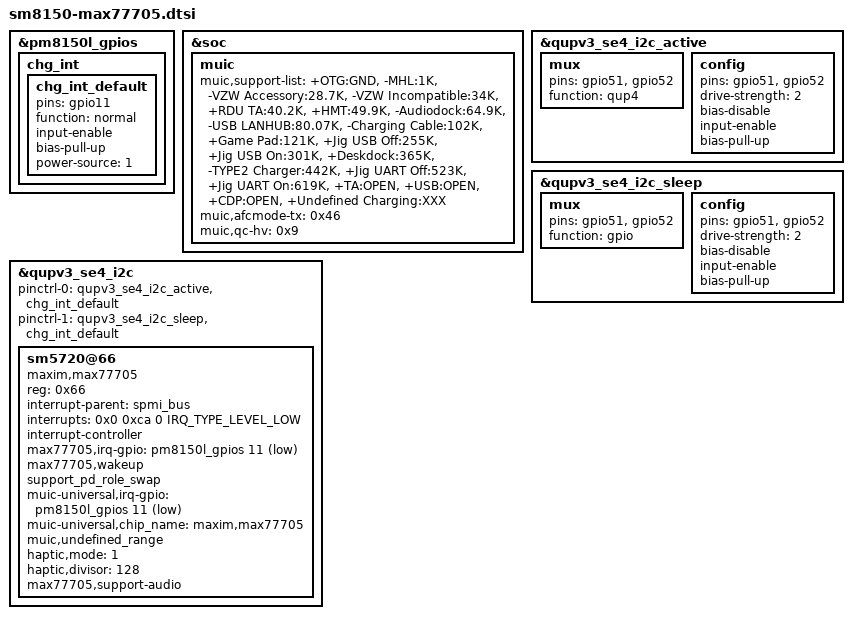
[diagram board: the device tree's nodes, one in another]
/* Copyright (c) 2012, The Linux Foundation. All rights reserved.
 *
 * This program is free software; you can redistribute it and/or modify
 * it under the terms of the GNU General Public License version 2 and
 * only version 2 as published by the Free Software Foundation.
 *
 * This program is distributed in the hope that it will be useful,
 * but WITHOUT ANY WARRANTY; without even the implied warranty of
 * MERCHANTABILITY or FITNESS FOR A PARTICULAR PURPOSE.  See the
 * GNU General Public License for more details.
 */

&pm8150l_gpios {
	chg_int {
		chg_int_default: chg_int_default {
			pins = "gpio11";
			function = "normal";
			input-enable;
			bias-pull-up;
			power-source = <1>;
		};
	};
};

&soc {
	muic {
		status = "okay";
		muic,support-list = "+OTG:GND",
				"-MHL:1K",
				"-VZW Accessory:28.7K",
				"-VZW Incompatible:34K",
				"+RDU TA:40.2K",
				"+HMT:49.9K",
				"-Audiodock:64.9K",
				"-USB LANHUB:80.07K",
				"-Charging Cable:102K",
				"+Game Pad:121K",
				"+Jig USB Off:255K",
				"+Jig USB On:301K",
				"+Deskdock:365K",
				"-TYPE2 Charger:442K",
				"+Jig UART Off:523K",
				"+Jig UART On:619K",
				"+TA:OPEN",
				"+USB:OPEN",
				"+CDP:OPEN",
				"+Undefined Charging:XXX";
		muic,afcmode-tx = /bits/ 8 <0x46>;
		muic,qc-hv = /bits/ 8 <0x9>;
	};
#if 0
	samsung,vibrator {
		compatible = "samsung_vib";
		pinctrl-names = "tlmm_motor_active","tlmm_motor_suspend";
		pinctrl-0 = <&motor_pwm_active>;
		pinctrl-1 = <&motor_pwm_suspend>;
		samsung,vib_pwm = <&tlmm 136 0>;
		samsung,vib_power = <&pm8150_gpios 10 0>;
		samsung,gp_clk = <0x00164000>;	// Address of GP1 clock
		samsung,chip_model = <4>;	// using max77705 driver
		samsung,support_multi_freq = <1>;
		status = "ok";
	};
#endif
};

		/* SE 4 pin mappings */
&qupv3_se4_i2c_active {
	mux {
		pins = "gpio51", "gpio52";
		function = "qup4";
	};

	config {
		pins = "gpio51", "gpio52";
		drive-strength = <2>;
		bias-disable;
		input-enable;
		bias-pull-up;
	};
};

&qupv3_se4_i2c_sleep {
	mux {
		pins = "gpio51", "gpio52";
		function = "gpio";
	};

	config {
		pins = "gpio51", "gpio52";
		drive-strength = <2>;
		bias-disable;
		input-enable;
		bias-pull-up;
	};
};

&qupv3_se4_i2c {
	status = "ok";

	pinctrl-0 = <&qupv3_se4_i2c_active &chg_int_default>;
	pinctrl-1 = <&qupv3_se4_i2c_sleep &chg_int_default>;

	sm5720@66 {
		compatible = "maxim,max77705";
			reg = <0x66>;
			interrupt-parent = <&spmi_bus>;
			interrupts = <0x0 0xca 0 IRQ_TYPE_LEVEL_LOW>;
			interrupt-names = "max77705_irq";
			interrupt-controller;
			max77705,irq-gpio = <&pm8150l_gpios 11 0x01>;
			max77705,wakeup;
			support_pd_role_swap;
			muic-universal,irq-gpio = <&pm8150l_gpios 11 0x01>;
			muic-universal,chip_name = "maxim,max77705";
			muic,undefined_range;
//			pinctrl-0 = <&muic_i2c_active>;
//			pinctrl-1 = <&muic_i2c_suspend>;
//			pinctrl-2 = <&chg_int_default>;
			haptic,mode = <1>;
			haptic,divisor = <128>;
			max77705,support-audio;
	};
};
